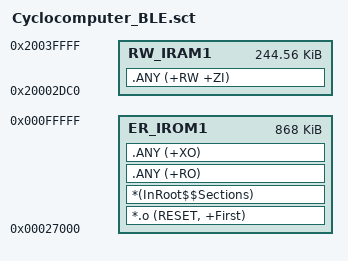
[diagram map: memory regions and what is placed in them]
; ******************************************************************
; *** Scatter-Loading Description File generated by Embedded IDE ***
; ******************************************************************

LR_IROM1 0x00027000 0x000d9000 {
	ER_IROM1 0x00027000 0x000d9000 {
		*.o (RESET, +First) 
		*(InRoot$$Sections) 
		.ANY (+RO) 
		.ANY (+XO) 
	}
	RW_IRAM1 0x20002dc0 0x0003d240 {
		.ANY (+RW +ZI) 
	}
}

